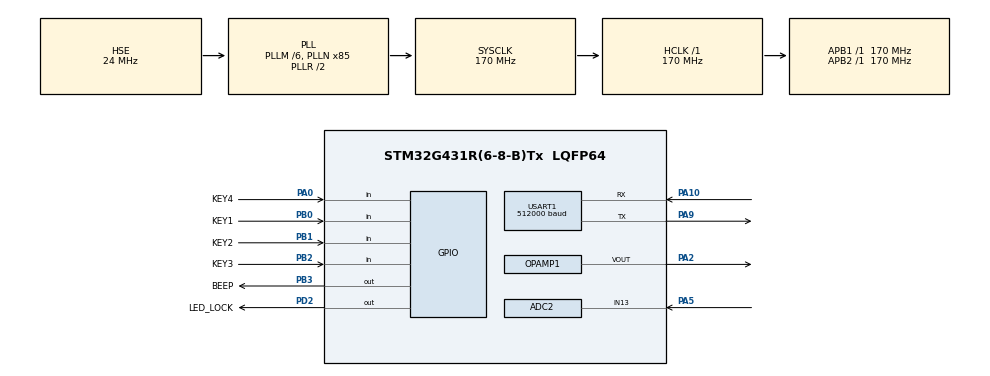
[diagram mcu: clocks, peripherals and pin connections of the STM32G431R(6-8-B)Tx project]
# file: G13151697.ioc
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ADC2.Channel-1\#ChannelRegularConversion=ADC_CHANNEL_13
ADC2.NbrOfConversionFlag=1
ADC2.OffsetNumber-1\#ChannelRegularConversion=ADC_OFFSET_NONE
ADC2.Rank-1\#ChannelRegularConversion=1
ADC2.SamplingTime-1\#ChannelRegularConversion=ADC_SAMPLETIME_47CYCLES_5
DAC3.DAC_Trigger_OUT1-DAC_OUT1_Int=DAC_TRIGGER_T2_TRGO
Dma.DAC3_CH1.0.Direction=DMA_MEMORY_TO_PERIPH
Dma.DAC3_CH1.0.EventEnable=DISABLE
Dma.DAC3_CH1.0.Instance=DMA1_Channel1
Dma.DAC3_CH1.0.MemDataAlignment=DMA_MDATAALIGN_HALFWORD
Dma.DAC3_CH1.0.MemInc=DMA_MINC_ENABLE
Dma.DAC3_CH1.0.Mode=DMA_CIRCULAR
Dma.DAC3_CH1.0.PeriphDataAlignment=DMA_PDATAALIGN_WORD
Dma.DAC3_CH1.0.PeriphInc=DMA_PINC_DISABLE
Dma.DAC3_CH1.0.Polarity=HAL_DMAMUX_REQ_GEN_RISING
Dma.DAC3_CH1.0.Priority=DMA_PRIORITY_LOW
Dma.DAC3_CH1.0.RequestNumber=1
Dma.DAC3_CH1.0.SignalID=NONE
Dma.DAC3_CH1.0.SyncEnable=DISABLE
Dma.DAC3_CH1.0.SyncPolarity=HAL_DMAMUX_SYNC_NO_EVENT
Dma.DAC3_CH1.0.SyncRequestNumber=1
Dma.DAC3_CH1.0.SyncSignalID=NONE
Dma.Request0=DAC3_CH1
Mcu.Family=STM32G4
Mcu.Name=STM32G431R(6-8-B)Tx
Mcu.Package=LQFP64
NVIC.DMA1_Channel1_IRQn=true\:0\:0\:false\:false\:true\:false\:true
NVIC.PriorityGroup=NVIC_PRIORITYGROUP_4
NVIC.USART1_IRQn=true\:0\:0\:false\:false\:true\:true\:true
OPAMP1.PowerMode=OPAMP_POWERMODE_HIGHSPEED
PA0.GPIO_Label=KEY4
PA0.Signal=GPIO_Input
PA10.Mode=Asynchronous
PA10.Signal=USART1_RX
PA2.Mode=Follower-DAC_OUT2-INP
PA2.Signal=OPAMP1_VOUT
PA5.Mode=IN13-Single-Ended
PA5.Signal=ADC2_IN13
PA9.Mode=Asynchronous
PA9.Signal=USART1_TX
PB0.GPIO_Label=KEY1
PB0.Signal=GPIO_Input
PB1.GPIO_Label=KEY2
PB1.Signal=GPIO_Input
PB2.GPIO_Label=KEY3
PB2.Signal=GPIO_Input
PB3.GPIO_Label=BEEP
PB3.PinState=GPIO_PIN_SET
PB3.Signal=GPIO_Output
PD2.GPIO_Label=LED_LOCK
PD2.Signal=GPIO_Output
PF0-OSC_IN.Mode=HSE-External-Oscillator
PF0-OSC_IN.Signal=RCC_OSC_IN
PF1-OSC_OUT.Mode=HSE-External-Oscillator
PF1-OSC_OUT.Signal=RCC_OSC_OUT
ProjectManager.HeapSize=0x200
ProjectManager.StackSize=0x400
ProjectManager.TargetToolchain=MDK-ARM V5
RCC.ADC12Freq_Value=170000000
RCC.AHBFreq_Value=170000000
RCC.APB1Freq_Value=170000000
RCC.APB1TimFreq_Value=170000000
RCC.APB2Freq_Value=170000000
RCC.APB2TimFreq_Value=170000000
RCC.CortexFreq_Value=170000000
RCC.EXTERNAL_CLOCK_VALUE=12288000
RCC.HCLKFreq_Value=170000000
RCC.HSE_VALUE=24000000
RCC.HSI48_VALUE=48000000
RCC.HSI_VALUE=16000000
RCC.LSE_VALUE=32768
RCC.PLLM=RCC_PLLM_DIV6
RCC.PLLN=85
RCC.PLLSourceVirtual=RCC_PLLSOURCE_HSE
RCC.RTCClockSelection=RCC_RTCCLKSOURCE_HSE_DIV32
RCC.SYSCLKFreq_VALUE=170000000
RCC.SYSCLKSource=RCC_SYSCLKSOURCE_PLLCLK
RCC.USBFreq_Value=170000000
RCC.VCOOutputFreq_Value=340000000
TIM2.AutoReloadPreload=TIM_AUTORELOAD_PRELOAD_ENABLE
TIM2.PeriodNoDither=169999
TIM2.TIM_MasterOutputTrigger=TIM_TRGO_UPDATE
USART1.BaudRate=512000
USART1.VirtualMode-Asynchronous=VM_ASYNC
VP_DAC3_VS_DACI1.Mode=DAC_OUT1_Int
VP_SYS_VS_DBSignals.Mode=DisableDeadBatterySignals
VP_TIM2_VS_ClockSourceINT.Mode=Internal
board=custom

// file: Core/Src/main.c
/* USER CODE BEGIN Header */
/**
  ******************************************************************************
  * @file           : main.c
  * @brief          : Main program body
  ******************************************************************************
  * @attention
  *
  * <h2><center>&copy; Copyright (c) 2022 STMicroelectronics.
  * All rights reserved.</center></h2>
  *
  * This software component is licensed by ST under BSD 3-Clause license,
  * the "License"; You may not use this file except in compliance with the
  * License. You may obtain a copy of the License at:
  *                        opensource.org/licenses/BSD-3-Clause
  *
  ******************************************************************************
  */
/* USER CODE END Header */
#include "main.h"
#include "adc.h"
#include "dac.h"
#include "dma.h"
#include "opamp.h"
#include "tim.h"
#include "usart.h"
#include "gpio.h"

/* USER CODE BEGIN Includes */
#include "bsp.h"
#include "bll.h"
#include "ui.h"

/* USER CODE END Includes */

/* USER CODE BEGIN PD */

//#define UART_SEND_ADC_DATA

/* USER CODE END PD */

/* USER CODE BEGIN PV */

//u8 UART_LED_Flag = 0;   // UART命令接收指示灯状态

/* USER CODE END PV */

void SystemClock_Config(void);
/* USER CODE BEGIN PFP */

//void LED_UART_Rx_Command_State_Task(void);

/* USER CODE END PFP */

int main(void)
{

  /* MCU Configuration--------------------------------------------------------*/

  /* Reset of all peripherals, Initializes the Flash interface and the Systick. */
  HAL_Init();

  /* Configure the system clock */
  SystemClock_Config();

  /* Initialize all configured peripherals */
  MX_GPIO_Init();
  MX_USART1_UART_Init();
  MX_ADC2_Init();
  MX_DMA_Init();
  MX_TIM2_Init();
  MX_DAC3_Init();
  MX_OPAMP1_Init();
  /* USER CODE BEGIN 2 */

  // 初始化相关参数 打开控制DAC定时器中断 并 使能DAC模块
  Signal_Generator_Init();

  // 开启串口接收中断
  Receive_Uart_Command_Init();

  // 初始LCD并显示界面
  UI_Init();

  /* USER CODE END 2 */

  /* Infinite loop */
  /* USER CODE BEGIN WHILE */

  while (1)
  {
      KEY_Task();  // 按键逻辑检测
      BEEP_Task(); // 蜂鸣器任务
      UI_Update_Task();  // 界面刷新任务

      UART_Send_AD_Data_Task();     // 实时数据发送任务
      UART_Check_Rx_Command_Task(); // 命令接收检查任务

    /* USER CODE END WHILE */

  }
}

void SystemClock_Config(void)
{
  RCC_OscInitTypeDef RCC_OscInitStruct = {0};
  RCC_ClkInitTypeDef RCC_ClkInitStruct = {0};
  RCC_PeriphCLKInitTypeDef PeriphClkInit = {0};

  /** Configure the main internal regulator output voltage
  */
  HAL_PWREx_ControlVoltageScaling(PWR_REGULATOR_VOLTAGE_SCALE1_BOOST);
  /** Initializes the RCC Oscillators according to the specified parameters
  * in the RCC_OscInitTypeDef structure.
  */
  RCC_OscInitStruct.OscillatorType = RCC_OSCILLATORTYPE_HSE;
  RCC_OscInitStruct.HSEState = RCC_HSE_ON;
  RCC_OscInitStruct.PLL.PLLState = RCC_PLL_ON;
  RCC_OscInitStruct.PLL.PLLSource = RCC_PLLSOURCE_HSE;
  RCC_OscInitStruct.PLL.PLLM = RCC_PLLM_DIV6;
  RCC_OscInitStruct.PLL.PLLN = 85;
  RCC_OscInitStruct.PLL.PLLP = RCC_PLLP_DIV2;
  RCC_OscInitStruct.PLL.PLLQ = RCC_PLLQ_DIV2;
  RCC_OscInitStruct.PLL.PLLR = RCC_PLLR_DIV2;
  if (HAL_RCC_OscConfig(&RCC_OscInitStruct) != HAL_OK)
  {
    Error_Handler();
  }
  /** Initializes the CPU, AHB and APB buses clocks
  */
  RCC_ClkInitStruct.ClockType = RCC_CLOCKTYPE_HCLK|RCC_CLOCKTYPE_SYSCLK
                              |RCC_CLOCKTYPE_PCLK1|RCC_CLOCKTYPE_PCLK2;
  RCC_ClkInitStruct.SYSCLKSource = RCC_SYSCLKSOURCE_PLLCLK;
  RCC_ClkInitStruct.AHBCLKDivider = RCC_SYSCLK_DIV1;
  RCC_ClkInitStruct.APB1CLKDivider = RCC_HCLK_DIV1;
  RCC_ClkInitStruct.APB2CLKDivider = RCC_HCLK_DIV1;

  if (HAL_RCC_ClockConfig(&RCC_ClkInitStruct, FLASH_LATENCY_4) != HAL_OK)
  {
    Error_Handler();
  }
  /** Initializes the peripherals clocks
  */
  PeriphClkInit.PeriphClockSelection = RCC_PERIPHCLK_USART1|RCC_PERIPHCLK_ADC12;
  PeriphClkInit.Usart1ClockSelection = RCC_USART1CLKSOURCE_PCLK2;
  PeriphClkInit.Adc12ClockSelection = RCC_ADC12CLKSOURCE_SYSCLK;
  if (HAL_RCCEx_PeriphCLKConfig(&PeriphClkInit) != HAL_OK)
  {
    Error_Handler();
  }
}

/* USER CODE BEGIN 4 */
/***************************************************/
/****************    LED部分      ******************/

//void LED_UART_Rx_Command_State_Task(void)
//{
//    if(UART_LED_Flag == 1)
//    {
//        LED_Disp(0x01);
//        if(SW_Timer_Tick[4] < HAL_GetTick())
//        {
//            LED_Disp(0x00);
//            UART_LED_Flag = 0;
//        }
//    }
//    else if(UART_LED_Flag == 2)
//    {
//        LED_Disp(0x80);
//        if(SW_Timer_Tick[4] < HAL_GetTick())
//        {
//            LED_Disp(0x00);
//            UART_LED_Flag = 0;
//        }
//    }
//}

/* USER CODE END 4 */

void Error_Handler(void)
{
  __disable_irq();
  while (1)
  {
  }
}

/************************ (C) COPYRIGHT STMicroelectronics *****END OF FILE****/
